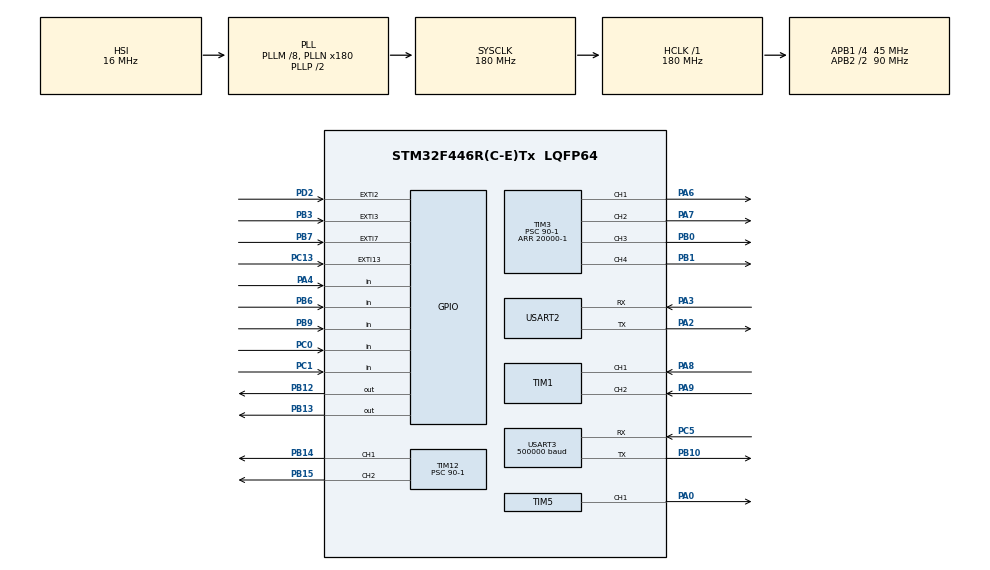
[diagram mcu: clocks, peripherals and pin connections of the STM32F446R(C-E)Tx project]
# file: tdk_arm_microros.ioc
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Dma.Request0=USART2_RX
Dma.Request1=USART2_TX
Dma.USART2_RX.0.Direction=DMA_PERIPH_TO_MEMORY
Dma.USART2_RX.0.FIFOMode=DMA_FIFOMODE_DISABLE
Dma.USART2_RX.0.Instance=DMA1_Stream5
Dma.USART2_RX.0.MemDataAlignment=DMA_MDATAALIGN_BYTE
Dma.USART2_RX.0.MemInc=DMA_MINC_ENABLE
Dma.USART2_RX.0.Mode=DMA_CIRCULAR
Dma.USART2_RX.0.PeriphDataAlignment=DMA_PDATAALIGN_BYTE
Dma.USART2_RX.0.PeriphInc=DMA_PINC_DISABLE
Dma.USART2_RX.0.Priority=DMA_PRIORITY_VERY_HIGH
Dma.USART2_TX.1.Direction=DMA_MEMORY_TO_PERIPH
Dma.USART2_TX.1.FIFOMode=DMA_FIFOMODE_DISABLE
Dma.USART2_TX.1.Instance=DMA1_Stream6
Dma.USART2_TX.1.MemDataAlignment=DMA_MDATAALIGN_BYTE
Dma.USART2_TX.1.MemInc=DMA_MINC_ENABLE
Dma.USART2_TX.1.Mode=DMA_NORMAL
Dma.USART2_TX.1.PeriphDataAlignment=DMA_PDATAALIGN_BYTE
Dma.USART2_TX.1.PeriphInc=DMA_PINC_DISABLE
Dma.USART2_TX.1.Priority=DMA_PRIORITY_VERY_HIGH
FREERTOS.Tasks01=defaultTask,24,3000,StartDefaultTask,As weak,NULL,Static,defaultTaskBuffer,defaultTaskControlBlock
FREERTOS.configUSE_NEWLIB_REENTRANT=1
Mcu.Family=STM32F4
Mcu.Name=STM32F446R(C-E)Tx
Mcu.Package=LQFP64
NVIC.DMA1_Stream5_IRQn=true\:5\:0\:false\:false\:true\:true\:false\:true\:true
NVIC.DMA1_Stream6_IRQn=true\:5\:0\:false\:false\:true\:true\:false\:true\:true
NVIC.EXTI15_10_IRQn=true\:5\:0\:false\:false\:true\:true\:true\:true\:true
NVIC.EXTI2_IRQn=true\:5\:0\:false\:false\:true\:true\:true\:true\:true
NVIC.EXTI3_IRQn=true\:5\:0\:false\:false\:true\:true\:true\:true\:true
NVIC.EXTI9_5_IRQn=true\:5\:0\:false\:false\:true\:true\:true\:true\:true
NVIC.PriorityGroup=NVIC_PRIORITYGROUP_4
NVIC.TIM4_IRQn=true\:5\:0\:false\:false\:true\:true\:true\:true\:true
NVIC.TIM6_DAC_IRQn=true\:15\:0\:false\:false\:true\:false\:false\:true\:true
NVIC.TimeBase=TIM6_DAC_IRQn
NVIC.TimeBaseIP=TIM6
NVIC.USART2_IRQn=true\:5\:0\:false\:false\:true\:true\:true\:true\:true
PA0-WKUP.Signal=S_TIM5_CH1
PA13.Mode=Serial_Wire
PA13.Signal=SYS_JTMS-SWDIO
PA14.Mode=Serial_Wire
PA14.Signal=SYS_JTCK-SWCLK
PA2.Mode=Asynchronous
PA2.Signal=USART2_TX
PA3.Mode=Asynchronous
PA3.Signal=USART2_RX
PA4.GPIO_PuPd=GPIO_PULLUP
PA4.Signal=GPIO_Input
PA6.Signal=S_TIM3_CH1
PA7.Signal=S_TIM3_CH2
PA8.Signal=S_TIM1_CH1
PA9.Signal=S_TIM1_CH2
PB0.Signal=S_TIM3_CH3
PB1.Signal=S_TIM3_CH4
PB10.Mode=Asynchronous
PB10.Signal=USART3_TX
PB12.Signal=GPIO_Output
PB13.Signal=GPIO_Output
PB14.Signal=S_TIM12_CH1
PB15.Signal=S_TIM12_CH2
PB3.GPIO_ModeDefaultEXTI=GPIO_MODE_IT_FALLING
PB3.GPIO_PuPd=GPIO_PULLUP
PB3.Signal=GPXTI3
PB6.GPIO_PuPd=GPIO_PULLUP
PB6.Signal=GPIO_Input
PB7.GPIO_ModeDefaultEXTI=GPIO_MODE_IT_FALLING
PB7.GPIO_PuPd=GPIO_PULLUP
PB7.Signal=GPXTI7
PB9.GPIO_PuPd=GPIO_PULLUP
PB9.Signal=GPIO_Input
PC0.GPIO_PuPd=GPIO_PULLUP
PC0.Signal=GPIO_Input
PC1.GPIO_PuPd=GPIO_PULLUP
PC1.Signal=GPIO_Input
PC13.GPIO_ModeDefaultEXTI=GPIO_MODE_IT_FALLING
PC13.GPIO_PuPd=GPIO_PULLUP
PC13.Signal=GPXTI13
PC5.Mode=Asynchronous
PC5.Signal=USART3_RX
PD2.GPIO_ModeDefaultEXTI=GPIO_MODE_IT_FALLING
PD2.GPIO_PuPd=GPIO_PULLUP
PD2.Signal=GPXTI2
ProjectManager.HeapSize=0x200
ProjectManager.StackSize=0x400
ProjectManager.TargetToolchain=STM32CubeIDE
RCC.AHBFreq_Value=180000000
RCC.APB1CLKDivider=RCC_HCLK_DIV4
RCC.APB1Freq_Value=45000000
RCC.APB1TimFreq_Value=90000000
RCC.APB2CLKDivider=RCC_HCLK_DIV2
RCC.APB2Freq_Value=90000000
RCC.APB2TimFreq_Value=180000000
RCC.CortexFreq_Value=180000000
RCC.HCLKFreq_Value=180000000
RCC.PLLM=8
RCC.PLLN=180
RCC.SYSCLKFreq_VALUE=180000000
RCC.SYSCLKSource=RCC_SYSCLKSOURCE_PLLCLK
RCC.USBFreq_Value=180000000
RCC.VCOOutputFreq_Value=360000000
SH.S_TIM12_CH1.0=TIM12_CH1,PWM Generation1 CH1
SH.S_TIM12_CH2.0=TIM12_CH2,PWM Generation2 CH2
SH.S_TIM1_CH1.0=TIM1_CH1,Encoder_Interface
SH.S_TIM1_CH2.0=TIM1_CH2,Encoder_Interface
SH.S_TIM3_CH1.0=TIM3_CH1,PWM Generation1 CH1
SH.S_TIM3_CH2.0=TIM3_CH2,PWM Generation2 CH2
SH.S_TIM3_CH3.0=TIM3_CH3,PWM Generation3 CH3
SH.S_TIM3_CH4.0=TIM3_CH4,PWM Generation4 CH4
SH.S_TIM5_CH1.0=TIM5_CH1,PWM Generation1 CH1
TIM1.EncoderMode=TIM_ENCODERMODE_TI12
TIM12.Channel-PWM\ Generation1\ CH1=TIM_CHANNEL_1
TIM12.Channel-PWM\ Generation2\ CH2=TIM_CHANNEL_2
TIM12.Period=1000-1
TIM12.Prescaler=90-1
TIM3.Channel-PWM\ Generation1\ CH1=TIM_CHANNEL_1
TIM3.Channel-PWM\ Generation2\ CH2=TIM_CHANNEL_2
TIM3.Channel-PWM\ Generation3\ CH3=TIM_CHANNEL_3
TIM3.Channel-PWM\ Generation4\ CH4=TIM_CHANNEL_4
TIM3.Period=20000-1
TIM3.Prescaler=90-1
TIM4.Period=10000-1
TIM4.Prescaler=90-1
TIM5.Channel-PWM\ Generation1\ CH1=TIM_CHANNEL_1
TIM5.Period=20000-1
TIM5.Prescaler=90-1
USART2.VirtualMode=VM_ASYNC
USART3.BaudRate=500000
USART3.VirtualMode=VM_ASYNC
VP_FREERTOS_VS_CMSIS_V2.Mode=CMSIS_V2
VP_SYS_VS_tim6.Mode=TIM6
VP_TIM4_VS_ClockSourceINT.Mode=Internal
board=custom

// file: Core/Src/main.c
/* USER CODE BEGIN Header */
/**
  ******************************************************************************
  * @file           : main.c
  * @brief          : Main program body
  ******************************************************************************
  * @attention
  *
  * Copyright (c) 2025 STMicroelectronics.
  * All rights reserved.
  *
  * This software is licensed under terms that can be found in the LICENSE file
  * in the root directory of this software component.
  * If no LICENSE file comes with this software, it is provided AS-IS.
  *
  ******************************************************************************
  */
/* USER CODE END Header */
#include "main.h"
#include "cmsis_os.h"

typedef StaticTask_t osStaticThreadDef_t;

TIM_HandleTypeDef htim1;
TIM_HandleTypeDef htim3;
TIM_HandleTypeDef htim4;
TIM_HandleTypeDef htim5;
TIM_HandleTypeDef htim12;

UART_HandleTypeDef huart2;
UART_HandleTypeDef huart3;
DMA_HandleTypeDef hdma_usart2_rx;
DMA_HandleTypeDef hdma_usart2_tx;

/* Definitions for defaultTask */
osThreadId_t defaultTaskHandle;
uint32_t defaultTaskBuffer[ 3000 ];
osStaticThreadDef_t defaultTaskControlBlock;
const osThreadAttr_t defaultTask_attributes = {
  .name = "defaultTask",
  .cb_mem = &defaultTaskControlBlock,
  .cb_size = sizeof(defaultTaskControlBlock),
  .stack_mem = &defaultTaskBuffer[0],
  .stack_size = sizeof(defaultTaskBuffer),
  .priority = (osPriority_t) osPriorityNormal,
};

void SystemClock_Config(void);
static void MX_GPIO_Init(void);
static void MX_DMA_Init(void);
static void MX_USART2_UART_Init(void);
static void MX_TIM1_Init(void);
static void MX_TIM5_Init(void);
static void MX_USART3_UART_Init(void);
static void MX_TIM4_Init(void);
static void MX_TIM12_Init(void);
static void MX_TIM3_Init(void);
void StartDefaultTask(void *argument);

int main(void)
{

  /* MCU Configuration--------------------------------------------------------*/

  /* Reset of all peripherals, Initializes the Flash interface and the Systick. */
  HAL_Init();

  /* Configure the system clock */
  SystemClock_Config();

  /* Initialize all configured peripherals */
  MX_GPIO_Init();
  MX_DMA_Init();
  MX_USART2_UART_Init();
  MX_TIM1_Init();
  MX_TIM5_Init();
  MX_USART3_UART_Init();
  MX_TIM4_Init();
  MX_TIM12_Init();
  MX_TIM3_Init();

  /* Init scheduler */
  osKernelInitialize();

  /* Create the thread(s) */
  /* creation of defaultTask */
  defaultTaskHandle = osThreadNew(StartDefaultTask, NULL, &defaultTask_attributes);

  /* Start scheduler */
  osKernelStart();

  /* We should never get here as control is now taken by the scheduler */

  /* Infinite loop */
  while (1)
  {

  }
}

void SystemClock_Config(void)
{
  RCC_OscInitTypeDef RCC_OscInitStruct = {0};
  RCC_ClkInitTypeDef RCC_ClkInitStruct = {0};

  /** Configure the main internal regulator output voltage
  */
  __HAL_RCC_PWR_CLK_ENABLE();
  __HAL_PWR_VOLTAGESCALING_CONFIG(PWR_REGULATOR_VOLTAGE_SCALE1);

  /** Initializes the RCC Oscillators according to the specified parameters
  * in the RCC_OscInitTypeDef structure.
  */
  RCC_OscInitStruct.OscillatorType = RCC_OSCILLATORTYPE_HSI;
  RCC_OscInitStruct.HSIState = RCC_HSI_ON;
  RCC_OscInitStruct.HSICalibrationValue = RCC_HSICALIBRATION_DEFAULT;
  RCC_OscInitStruct.PLL.PLLState = RCC_PLL_ON;
  RCC_OscInitStruct.PLL.PLLSource = RCC_PLLSOURCE_HSI;
  RCC_OscInitStruct.PLL.PLLM = 8;
  RCC_OscInitStruct.PLL.PLLN = 180;
  RCC_OscInitStruct.PLL.PLLP = RCC_PLLP_DIV2;
  RCC_OscInitStruct.PLL.PLLQ = 2;
  RCC_OscInitStruct.PLL.PLLR = 2;
  if (HAL_RCC_OscConfig(&RCC_OscInitStruct) != HAL_OK)
  {
    Error_Handler();
  }

  /** Activate the Over-Drive mode
  */
  if (HAL_PWREx_EnableOverDrive() != HAL_OK)
  {
    Error_Handler();
  }

  /** Initializes the CPU, AHB and APB buses clocks
  */
  RCC_ClkInitStruct.ClockType = RCC_CLOCKTYPE_HCLK|RCC_CLOCKTYPE_SYSCLK
                              |RCC_CLOCKTYPE_PCLK1|RCC_CLOCKTYPE_PCLK2;
  RCC_ClkInitStruct.SYSCLKSource = RCC_SYSCLKSOURCE_PLLCLK;
  RCC_ClkInitStruct.AHBCLKDivider = RCC_SYSCLK_DIV1;
  RCC_ClkInitStruct.APB1CLKDivider = RCC_HCLK_DIV4;
  RCC_ClkInitStruct.APB2CLKDivider = RCC_HCLK_DIV2;

  if (HAL_RCC_ClockConfig(&RCC_ClkInitStruct, FLASH_LATENCY_5) != HAL_OK)
  {
    Error_Handler();
  }
}

static void MX_TIM1_Init(void)
{

  TIM_Encoder_InitTypeDef sConfig = {0};
  TIM_MasterConfigTypeDef sMasterConfig = {0};

  htim1.Instance = TIM1;
  htim1.Init.Prescaler = 0;
  htim1.Init.CounterMode = TIM_COUNTERMODE_UP;
  htim1.Init.Period = 65535;
  htim1.Init.ClockDivision = TIM_CLOCKDIVISION_DIV1;
  htim1.Init.RepetitionCounter = 0;
  htim1.Init.AutoReloadPreload = TIM_AUTORELOAD_PRELOAD_DISABLE;
  sConfig.EncoderMode = TIM_ENCODERMODE_TI12;
  sConfig.IC1Polarity = TIM_ICPOLARITY_RISING;
  sConfig.IC1Selection = TIM_ICSELECTION_DIRECTTI;
  sConfig.IC1Prescaler = TIM_ICPSC_DIV1;
  sConfig.IC1Filter = 0;
  sConfig.IC2Polarity = TIM_ICPOLARITY_RISING;
  sConfig.IC2Selection = TIM_ICSELECTION_DIRECTTI;
  sConfig.IC2Prescaler = TIM_ICPSC_DIV1;
  sConfig.IC2Filter = 0;
  if (HAL_TIM_Encoder_Init(&htim1, &sConfig) != HAL_OK)
  {
    Error_Handler();
  }
  sMasterConfig.MasterOutputTrigger = TIM_TRGO_RESET;
  sMasterConfig.MasterSlaveMode = TIM_MASTERSLAVEMODE_DISABLE;
  if (HAL_TIMEx_MasterConfigSynchronization(&htim1, &sMasterConfig) != HAL_OK)
  {
    Error_Handler();
  }

}

static void MX_TIM3_Init(void)
{

  TIM_MasterConfigTypeDef sMasterConfig = {0};
  TIM_OC_InitTypeDef sConfigOC = {0};

  htim3.Instance = TIM3;
  htim3.Init.Prescaler = 90-1;
  htim3.Init.CounterMode = TIM_COUNTERMODE_UP;
  htim3.Init.Period = 20000-1;
  htim3.Init.ClockDivision = TIM_CLOCKDIVISION_DIV1;
  htim3.Init.AutoReloadPreload = TIM_AUTORELOAD_PRELOAD_DISABLE;
  if (HAL_TIM_PWM_Init(&htim3) != HAL_OK)
  {
    Error_Handler();
  }
  sMasterConfig.MasterOutputTrigger = TIM_TRGO_RESET;
  sMasterConfig.MasterSlaveMode = TIM_MASTERSLAVEMODE_DISABLE;
  if (HAL_TIMEx_MasterConfigSynchronization(&htim3, &sMasterConfig) != HAL_OK)
  {
    Error_Handler();
  }
  sConfigOC.OCMode = TIM_OCMODE_PWM1;
  sConfigOC.Pulse = 0;
  sConfigOC.OCPolarity = TIM_OCPOLARITY_HIGH;
  sConfigOC.OCFastMode = TIM_OCFAST_DISABLE;
  if (HAL_TIM_PWM_ConfigChannel(&htim3, &sConfigOC, TIM_CHANNEL_1) != HAL_OK)
  {
    Error_Handler();
  }
  if (HAL_TIM_PWM_ConfigChannel(&htim3, &sConfigOC, TIM_CHANNEL_2) != HAL_OK)
  {
    Error_Handler();
  }
  if (HAL_TIM_PWM_ConfigChannel(&htim3, &sConfigOC, TIM_CHANNEL_3) != HAL_OK)
  {
    Error_Handler();
  }
  if (HAL_TIM_PWM_ConfigChannel(&htim3, &sConfigOC, TIM_CHANNEL_4) != HAL_OK)
  {
    Error_Handler();
  }
  HAL_TIM_MspPostInit(&htim3);

}

static void MX_TIM4_Init(void)
{

  TIM_ClockConfigTypeDef sClockSourceConfig = {0};
  TIM_MasterConfigTypeDef sMasterConfig = {0};

  htim4.Instance = TIM4;
  htim4.Init.Prescaler = 90-1;
  htim4.Init.CounterMode = TIM_COUNTERMODE_UP;
  htim4.Init.Period = 10000-1;
  htim4.Init.ClockDivision = TIM_CLOCKDIVISION_DIV1;
  htim4.Init.AutoReloadPreload = TIM_AUTORELOAD_PRELOAD_DISABLE;
  if (HAL_TIM_Base_Init(&htim4) != HAL_OK)
  {
    Error_Handler();
  }
  sClockSourceConfig.ClockSource = TIM_CLOCKSOURCE_INTERNAL;
  if (HAL_TIM_ConfigClockSource(&htim4, &sClockSourceConfig) != HAL_OK)
  {
    Error_Handler();
  }
  sMasterConfig.MasterOutputTrigger = TIM_TRGO_RESET;
  sMasterConfig.MasterSlaveMode = TIM_MASTERSLAVEMODE_DISABLE;
  if (HAL_TIMEx_MasterConfigSynchronization(&htim4, &sMasterConfig) != HAL_OK)
  {
    Error_Handler();
  }

}

static void MX_TIM5_Init(void)
{

  TIM_MasterConfigTypeDef sMasterConfig = {0};
  TIM_OC_InitTypeDef sConfigOC = {0};

  htim5.Instance = TIM5;
  htim5.Init.Prescaler = 90-1;
  htim5.Init.CounterMode = TIM_COUNTERMODE_UP;
  htim5.Init.Period = 20000-1;
  htim5.Init.ClockDivision = TIM_CLOCKDIVISION_DIV1;
  htim5.Init.AutoReloadPreload = TIM_AUTORELOAD_PRELOAD_DISABLE;
  if (HAL_TIM_PWM_Init(&htim5) != HAL_OK)
  {
    Error_Handler();
  }
  sMasterConfig.MasterOutputTrigger = TIM_TRGO_RESET;
  sMasterConfig.MasterSlaveMode = TIM_MASTERSLAVEMODE_DISABLE;
  if (HAL_TIMEx_MasterConfigSynchronization(&htim5, &sMasterConfig) != HAL_OK)
  {
    Error_Handler();
  }
  sConfigOC.OCMode = TIM_OCMODE_PWM1;
  sConfigOC.Pulse = 0;
  sConfigOC.OCPolarity = TIM_OCPOLARITY_HIGH;
  sConfigOC.OCFastMode = TIM_OCFAST_DISABLE;
  if (HAL_TIM_PWM_ConfigChannel(&htim5, &sConfigOC, TIM_CHANNEL_1) != HAL_OK)
  {
    Error_Handler();
  }
  HAL_TIM_MspPostInit(&htim5);

}

static void MX_TIM12_Init(void)
{

  TIM_OC_InitTypeDef sConfigOC = {0};

  htim12.Instance = TIM12;
  htim12.Init.Prescaler = 90-1;
  htim12.Init.CounterMode = TIM_COUNTERMODE_UP;
  htim12.Init.Period = 1000-1;
  htim12.Init.ClockDivision = TIM_CLOCKDIVISION_DIV1;
  htim12.Init.AutoReloadPreload = TIM_AUTORELOAD_PRELOAD_DISABLE;
  if (HAL_TIM_PWM_Init(&htim12) != HAL_OK)
  {
    Error_Handler();
  }
  sConfigOC.OCMode = TIM_OCMODE_PWM1;
  sConfigOC.Pulse = 0;
  sConfigOC.OCPolarity = TIM_OCPOLARITY_HIGH;
  sConfigOC.OCFastMode = TIM_OCFAST_DISABLE;
  if (HAL_TIM_PWM_ConfigChannel(&htim12, &sConfigOC, TIM_CHANNEL_1) != HAL_OK)
  {
    Error_Handler();
  }
  if (HAL_TIM_PWM_ConfigChannel(&htim12, &sConfigOC, TIM_CHANNEL_2) != HAL_OK)
  {
    Error_Handler();
  }
  HAL_TIM_MspPostInit(&htim12);

}

static void MX_USART2_UART_Init(void)
{

  huart2.Instance = USART2;
  huart2.Init.BaudRate = 115200;
  huart2.Init.WordLength = UART_WORDLENGTH_8B;
  huart2.Init.StopBits = UART_STOPBITS_1;
  huart2.Init.Parity = UART_PARITY_NONE;
  huart2.Init.Mode = UART_MODE_TX_RX;
  huart2.Init.HwFlowCtl = UART_HWCONTROL_NONE;
  huart2.Init.OverSampling = UART_OVERSAMPLING_16;
  if (HAL_UART_Init(&huart2) != HAL_OK)
  {
    Error_Handler();
  }

}

static void MX_USART3_UART_Init(void)
{

  huart3.Instance = USART3;
  huart3.Init.BaudRate = 500000;
  huart3.Init.WordLength = UART_WORDLENGTH_8B;
  huart3.Init.StopBits = UART_STOPBITS_1;
  huart3.Init.Parity = UART_PARITY_NONE;
  huart3.Init.Mode = UART_MODE_TX_RX;
  huart3.Init.HwFlowCtl = UART_HWCONTROL_NONE;
  huart3.Init.OverSampling = UART_OVERSAMPLING_16;
  if (HAL_UART_Init(&huart3) != HAL_OK)
  {
    Error_Handler();
  }

}

static void MX_DMA_Init(void)
{

  /* DMA controller clock enable */
  __HAL_RCC_DMA1_CLK_ENABLE();

  /* DMA interrupt init */
  /* DMA1_Stream5_IRQn interrupt configuration */
  HAL_NVIC_SetPriority(DMA1_Stream5_IRQn, 5, 0);
  HAL_NVIC_EnableIRQ(DMA1_Stream5_IRQn);
  /* DMA1_Stream6_IRQn interrupt configuration */
  HAL_NVIC_SetPriority(DMA1_Stream6_IRQn, 5, 0);
  HAL_NVIC_EnableIRQ(DMA1_Stream6_IRQn);

}

static void MX_GPIO_Init(void)
{
  GPIO_InitTypeDef GPIO_InitStruct = {0};

  /* GPIO Ports Clock Enable */
  __HAL_RCC_GPIOC_CLK_ENABLE();
  __HAL_RCC_GPIOA_CLK_ENABLE();
  __HAL_RCC_GPIOB_CLK_ENABLE();
  __HAL_RCC_GPIOD_CLK_ENABLE();

  /*Configure GPIO pin Output Level */
  HAL_GPIO_WritePin(GPIOB, GPIO_PIN_12|GPIO_PIN_13, GPIO_PIN_RESET);

  /*Configure GPIO pin : PC13 */
  GPIO_InitStruct.Pin = GPIO_PIN_13;
  GPIO_InitStruct.Mode = GPIO_MODE_IT_FALLING;
  GPIO_InitStruct.Pull = GPIO_PULLUP;
  HAL_GPIO_Init(GPIOC, &GPIO_InitStruct);

  /*Configure GPIO pins : PC0 PC1 */
  GPIO_InitStruct.Pin = GPIO_PIN_0|GPIO_PIN_1;
  GPIO_InitStruct.Mode = GPIO_MODE_INPUT;
  GPIO_InitStruct.Pull = GPIO_PULLUP;
  HAL_GPIO_Init(GPIOC, &GPIO_InitStruct);

  /*Configure GPIO pin : PA4 */
  GPIO_InitStruct.Pin = GPIO_PIN_4;
  GPIO_InitStruct.Mode = GPIO_MODE_INPUT;
  GPIO_InitStruct.Pull = GPIO_PULLUP;
  HAL_GPIO_Init(GPIOA, &GPIO_InitStruct);

  /*Configure GPIO pins : PB12 PB13 */
  GPIO_InitStruct.Pin = GPIO_PIN_12|GPIO_PIN_13;
  GPIO_InitStruct.Mode = GPIO_MODE_OUTPUT_PP;
  GPIO_InitStruct.Pull = GPIO_NOPULL;
  GPIO_InitStruct.Speed = GPIO_SPEED_FREQ_LOW;
  HAL_GPIO_Init(GPIOB, &GPIO_InitStruct);

  /*Configure GPIO pin : PD2 */
  GPIO_InitStruct.Pin = GPIO_PIN_2;
  GPIO_InitStruct.Mode = GPIO_MODE_IT_FALLING;
  GPIO_InitStruct.Pull = GPIO_PULLUP;
  HAL_GPIO_Init(GPIOD, &GPIO_InitStruct);

  /*Configure GPIO pins : PB3 PB7 */
  GPIO_InitStruct.Pin = GPIO_PIN_3|GPIO_PIN_7;
  GPIO_InitStruct.Mode = GPIO_MODE_IT_FALLING;
  GPIO_InitStruct.Pull = GPIO_PULLUP;
  HAL_GPIO_Init(GPIOB, &GPIO_InitStruct);

  /*Configure GPIO pins : PB6 PB9 */
  GPIO_InitStruct.Pin = GPIO_PIN_6|GPIO_PIN_9;
  GPIO_InitStruct.Mode = GPIO_MODE_INPUT;
  GPIO_InitStruct.Pull = GPIO_PULLUP;
  HAL_GPIO_Init(GPIOB, &GPIO_InitStruct);

  /* EXTI interrupt init*/
  HAL_NVIC_SetPriority(EXTI2_IRQn, 5, 0);
  HAL_NVIC_EnableIRQ(EXTI2_IRQn);

  HAL_NVIC_SetPriority(EXTI3_IRQn, 5, 0);
  HAL_NVIC_EnableIRQ(EXTI3_IRQn);

  HAL_NVIC_SetPriority(EXTI9_5_IRQn, 5, 0);
  HAL_NVIC_EnableIRQ(EXTI9_5_IRQn);

  HAL_NVIC_SetPriority(EXTI15_10_IRQn, 5, 0);
  HAL_NVIC_EnableIRQ(EXTI15_10_IRQn);

}

__weak void StartDefaultTask(void *argument)
{
  for(;;)
  {
    osDelay(1);
  }
}

__weak void HAL_TIM_PeriodElapsedCallback(TIM_HandleTypeDef *htim)
{
  /* USER CODE BEGIN Callback 0 */
//////
  /* USER CODE END Callback 0 */
  if (htim->Instance == TIM6)
  {
    HAL_IncTick();
  }
  /* USER CODE BEGIN Callback 1 */
////
  /* USER CODE END Callback 1 */
}

void Error_Handler(void)
{
  __disable_irq();
  while (1)
  {
  }
}
